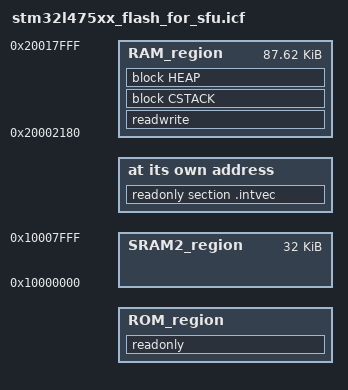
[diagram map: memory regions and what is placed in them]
/*###ICF### Section handled by ICF editor, don't touch! ****/
/*-Editor annotation file-*/
/* IcfEditorFile="$TOOLKIT_DIR$\config\ide\IcfEditor\cortex_v1_0.xml" */
/*-Specials-*/
define memory mem with size = 4G;

include "../../../SB_SFU/EWARM/stm32l476xx_flash_fwimg.icf";

define symbol __ICFEDIT_intvec_start__ =  __ICFEDIT_region_SLOT_0_start__ + 512;
export symbol __ICFEDIT_intvec_start__;
/*-Memory Regions-*/
define symbol __ICFEDIT_region_ROM_start__   = __ICFEDIT_intvec_start__;
define symbol __ICFEDIT_region_ROM_end__     =  __ICFEDIT_region_SLOT_0_end__ ;
define symbol __ICFEDIT_region_RAM_start__   = 0x20002180;
define symbol __ICFEDIT_region_RAM_end__     = 0x20017FFF;
define symbol __ICFEDIT_region_SRAM2_start__ = 0x10000000;
define symbol __ICFEDIT_region_SRAM2_end__   = 0x10007FFF;


/*-Sizes-*/
define symbol __ICFEDIT_size_cstack__ = 0x2000;
define symbol __ICFEDIT_size_heap__   = 0x11000;
/**** End of ICF editor section. ###ICF###*/

/* Definition of the static memory section for TLS certificates, keys, and wifi configuration data at the end of the first bank:
 *  Provision of 16Kbytes , aligned with end of SLOT1
 */

define symbol __ICFEDIT_region_FIXED_LOC_start__ = __ICFEDIT_region_SLOT_1_end__ + 1 ;
export	symbol __ICFEDIT_region_FIXED_LOC_start__;

define region ROM_region      = mem:[from __ICFEDIT_region_ROM_start__   to __ICFEDIT_region_FIXED_LOC_start__ ] ;
define region RAM_region      = mem:[from __ICFEDIT_region_RAM_start__   to __ICFEDIT_region_RAM_end__];
define region SRAM2_region    = mem:[from __ICFEDIT_region_SRAM2_start__   to __ICFEDIT_region_SRAM2_end__];

define block CSTACK    with alignment = 8, size = __ICFEDIT_size_cstack__   { };
define block HEAP      with alignment = 8, size = __ICFEDIT_size_heap__     { };

initialize by copy { readwrite };
do not initialize  { section .noinit };

place at address mem:__ICFEDIT_intvec_start__ { readonly section .intvec };

place in ROM_region   { readonly };
place in RAM_region   { readwrite,
                        block CSTACK, block HEAP };
place in SRAM2_region { };

